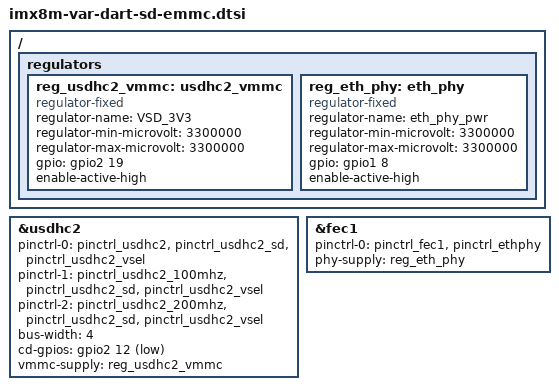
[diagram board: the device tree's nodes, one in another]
/*
 * Copyright 2017 NXP
 * Copyright 2018-2019 Variscite Ltd.
 *
 * This program is free software; you can redistribute it and/or
 * modify it under the terms of the GNU General Public License
 * as published by the Free Software Foundation; either version 2
 * of the License, or (at your option) any later version.
 *
 * This program is distributed in the hope that it will be useful,
 * but WITHOUT ANY WARRANTY; without even the implied warranty of
 * MERCHANTABILITY or FITNESS FOR A PARTICULAR PURPOSE.  See the
 * GNU General Public License for more details.
 */

/ {
	regulators {
		reg_usdhc2_vmmc: usdhc2_vmmc {
			compatible = "regulator-fixed";
			regulator-name = "VSD_3V3";
			regulator-min-microvolt = <3300000>;
			regulator-max-microvolt = <3300000>;
			gpio = <&gpio2 19 GPIO_ACTIVE_HIGH>;
			enable-active-high;
		};

		reg_eth_phy: eth_phy {
			compatible = "regulator-fixed";
			regulator-name = "eth_phy_pwr";
			regulator-min-microvolt = <3300000>;
			regulator-max-microvolt = <3300000>;
			gpio = <&gpio1 8 GPIO_ACTIVE_HIGH>;
			enable-active-high;
		};
	};
};

/* SD card */
&usdhc2 {
	pinctrl-names = "default", "state_100mhz", "state_200mhz";
	pinctrl-0 = <&pinctrl_usdhc2>, <&pinctrl_usdhc2_sd>, <&pinctrl_usdhc2_vsel>; 
	pinctrl-1 = <&pinctrl_usdhc2_100mhz>, <&pinctrl_usdhc2_sd>, <&pinctrl_usdhc2_vsel>;
	pinctrl-2 = <&pinctrl_usdhc2_200mhz>, <&pinctrl_usdhc2_sd>, <&pinctrl_usdhc2_vsel>;
	bus-width = <4>;
	cd-gpios = <&gpio2 12 GPIO_ACTIVE_LOW>;
	vmmc-supply = <&reg_usdhc2_vmmc>;
	status = "okay";
};

&fec1 {
	pinctrl-names = "default";
	pinctrl-0 = <&pinctrl_fec1>, <&pinctrl_ethphy>;
	phy-supply = <&reg_eth_phy>;
};

